# MSS_CTRL_MSS_CTRL register map
Vendor: Texas Instruments
Registers are 32-bit, read-only, reset 0x0 unless marked. A register's access mark holds for its fields unless they carry their own. Offsets are as the file gives them; [hi:lo] are bit positions; {n}, {i} and the like mark numbered series; 'fields as' and 'values as' point back to an identical list.

## MSS_CTRL_MSS_CTRL (part 3 of 5)
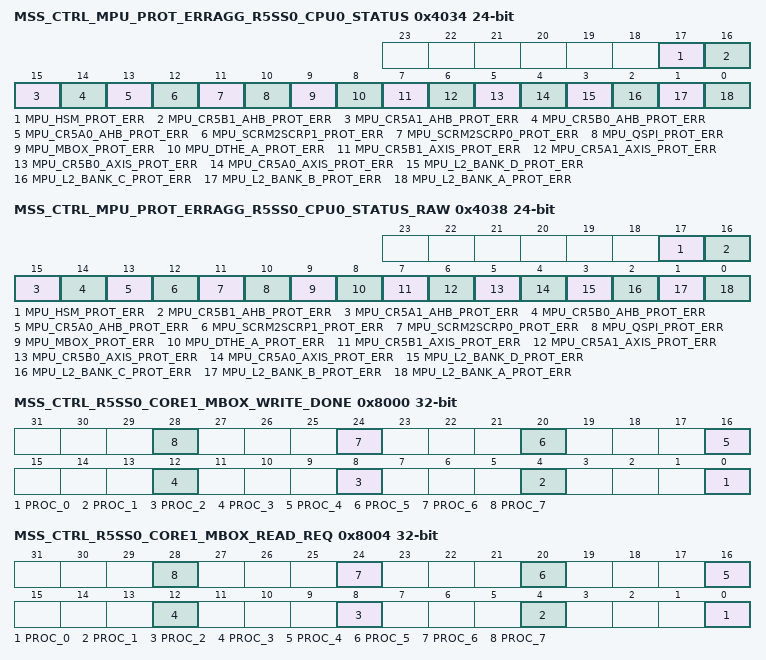
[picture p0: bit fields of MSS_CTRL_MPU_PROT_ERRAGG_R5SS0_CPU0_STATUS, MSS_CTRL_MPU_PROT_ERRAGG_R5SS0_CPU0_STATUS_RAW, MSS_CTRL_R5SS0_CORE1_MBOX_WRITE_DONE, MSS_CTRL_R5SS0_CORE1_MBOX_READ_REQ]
0x4034 MSS_CTRL_MPU_PROT_ERRAGG_R5SS0_CPU0_STATUS 24-bit rw
  [17] MPU_HSM_PROT_ERR — Status of Error from MPU_PROT_INTR. Set only if Interupt is unmasked in MPU_PROT_INTR_ERRAGG_MASKWrie 0x1 to clear this Error.
  [16] MPU_CR5B1_AHB_PROT_ERR — Status of Error from MPU_PROT_INTR. Set only if Interupt is unmasked in MPU_PROT_INTR_ERRAGG_MASKWrie 0x1 to clear this Error.
  [15] MPU_CR5A1_AHB_PROT_ERR — Status of Error from MPU_PROT_INTR. Set only if Interupt is unmasked in MPU_PROT_INTR_ERRAGG_MASKWrie 0x1 to clear this Error.
  [14] MPU_CR5B0_AHB_PROT_ERR — Status of Error from MPU_PROT_INTR. Set only if Interupt is unmasked in MPU_PROT_INTR_ERRAGG_MASKWrie 0x1 to clear this Error.
  [13] MPU_CR5A0_AHB_PROT_ERR — Status of Error from MPU_PROT_INTR. Set only if Interupt is unmasked in MPU_PROT_INTR_ERRAGG_MASKWrie 0x1 to clear this Error.
  [12] MPU_SCRM2SCRP1_PROT_ERR — Status of Error from MPU_PROT_INTR. Set only if Interupt is unmasked in MPU_PROT_INTR_ERRAGG_MASKWrie 0x1 to clear this Error.
  [11] MPU_SCRM2SCRP0_PROT_ERR — Status of Error from MPU_PROT_INTR. Set only if Interupt is unmasked in MPU_PROT_INTR_ERRAGG_MASKWrie 0x1 to clear this Error.
  [10] MPU_QSPI_PROT_ERR — Status of Error from MPU_PROT_INTR. Set only if Interupt is unmasked in MPU_PROT_INTR_ERRAGG_MASKWrie 0x1 to clear this Error.
  [9] MPU_MBOX_PROT_ERR — Status of Error from MPU_PROT_INTR. Set only if Interupt is unmasked in MPU_PROT_INTR_ERRAGG_MASKWrie 0x1 to clear this Error.
  [8] MPU_DTHE_A_PROT_ERR — Status of Error from MPU_PROT_INTR. Set only if Interupt is unmasked in MPU_PROT_INTR_ERRAGG_MASKWrie 0x1 to clear this Error.
  [7] MPU_CR5B1_AXIS_PROT_ERR — Status of Error from MPU_PROT_INTR. Set only if Interupt is unmasked in MPU_PROT_INTR_ERRAGG_MASKWrie 0x1 to clear this Error.
  [6] MPU_CR5A1_AXIS_PROT_ERR — Status of Error from MPU_PROT_INTR. Set only if Interupt is unmasked in MPU_PROT_INTR_ERRAGG_MASKWrie 0x1 to clear this Error.
  [5] MPU_CR5B0_AXIS_PROT_ERR — Status of Error from MPU_PROT_INTR. Set only if Interupt is unmasked in MPU_PROT_INTR_ERRAGG_MASKWrie 0x1 to clear this Error.
  [4] MPU_CR5A0_AXIS_PROT_ERR — Status of Error from MPU_PROT_INTR. Set only if Interupt is unmasked in MPU_PROT_INTR_ERRAGG_MASKWrie 0x1 to clear this Error.
  [3] MPU_L2_BANK_D_PROT_ERR — Status of Error from MPU_PROT_INTR. Set only if Interupt is unmasked in MPU_PROT_INTR_ERRAGG_MASKWrie 0x1 to clear this Error.
  [2] MPU_L2_BANK_C_PROT_ERR — Status of Error from MPU_PROT_INTR. Set only if Interupt is unmasked in MPU_PROT_INTR_ERRAGG_MASKWrie 0x1 to clear this Error.
  [1] MPU_L2_BANK_B_PROT_ERR — Status of Error from MPU_PROT_INTR. Set only if Interupt is unmasked in MPU_PROT_INTR_ERRAGG_MASKWrie 0x1 to clear this Error.
  [0] MPU_L2_BANK_A_PROT_ERR — Status of Error from MPU_PROT_INTR. Set only if Interupt is unmasked in MPU_PROT_INTR_ERRAGG_MASKWrie 0x1 to clear this Error.
0x4038 MSS_CTRL_MPU_PROT_ERRAGG_R5SS0_CPU0_STATUS_RAW 24-bit rw
  [17] MPU_HSM_PROT_ERR — Raw Status of Error from MPU_PROT_INTR. Set irrespective if the Interupt is masked or unmasked in MPU_PROT_INTR_ERRAGG_MASK
  [16] MPU_CR5B1_AHB_PROT_ERR — Raw Status of Error from MPU_PROT_INTR. Set irrespective if the Interupt is masked or unmasked in MPU_PROT_INTR_ERRAGG_MASK
  [15] MPU_CR5A1_AHB_PROT_ERR — Raw Status of Error from MPU_PROT_INTR. Set irrespective if the Interupt is masked or unmasked in MPU_PROT_INTR_ERRAGG_MASK
  [14] MPU_CR5B0_AHB_PROT_ERR — Raw Status of Error from MPU_PROT_INTR. Set irrespective if the Interupt is masked or unmasked in MPU_PROT_INTR_ERRAGG_MASK
  [13] MPU_CR5A0_AHB_PROT_ERR — Raw Status of Error from MPU_PROT_INTR. Set irrespective if the Interupt is masked or unmasked in MPU_PROT_INTR_ERRAGG_MASK
  [12] MPU_SCRM2SCRP1_PROT_ERR — Raw Status of Error from MPU_PROT_INTR. Set irrespective if the Interupt is masked or unmasked in MPU_PROT_INTR_ERRAGG_MASK
  [11] MPU_SCRM2SCRP0_PROT_ERR — Raw Status of Error from MPU_PROT_INTR. Set irrespective if the Interupt is masked or unmasked in MPU_PROT_INTR_ERRAGG_MASK
  [10] MPU_QSPI_PROT_ERR — Raw Status of Error from MPU_PROT_INTR. Set irrespective if the Interupt is masked or unmasked in MPU_PROT_INTR_ERRAGG_MASK
  [9] MPU_MBOX_PROT_ERR — Raw Status of Error from MPU_PROT_INTR. Set irrespective if the Interupt is masked or unmasked in MPU_PROT_INTR_ERRAGG_MASK
  [8] MPU_DTHE_A_PROT_ERR — Raw Status of Error from MPU_PROT_INTR. Set irrespective if the Interupt is masked or unmasked in MPU_PROT_INTR_ERRAGG_MASK
  [7] MPU_CR5B1_AXIS_PROT_ERR — Raw Status of Error from MPU_PROT_INTR. Set irrespective if the Interupt is masked or unmasked in MPU_PROT_INTR_ERRAGG_MASK
  [6] MPU_CR5A1_AXIS_PROT_ERR — Raw Status of Error from MPU_PROT_INTR. Set irrespective if the Interupt is masked or unmasked in MPU_PROT_INTR_ERRAGG_MASK
  [5] MPU_CR5B0_AXIS_PROT_ERR — Raw Status of Error from MPU_PROT_INTR. Set irrespective if the Interupt is masked or unmasked in MPU_PROT_INTR_ERRAGG_MASK
  [4] MPU_CR5A0_AXIS_PROT_ERR — Raw Status of Error from MPU_PROT_INTR. Set irrespective if the Interupt is masked or unmasked in MPU_PROT_INTR_ERRAGG_MASK
  [3] MPU_L2_BANK_D_PROT_ERR — Raw Status of Error from MPU_PROT_INTR. Set irrespective if the Interupt is masked or unmasked in MPU_PROT_INTR_ERRAGG_MASK
  [2] MPU_L2_BANK_C_PROT_ERR — Raw Status of Error from MPU_PROT_INTR. Set irrespective if the Interupt is masked or unmasked in MPU_PROT_INTR_ERRAGG_MASK
  [1] MPU_L2_BANK_B_PROT_ERR — Raw Status of Error from MPU_PROT_INTR. Set irrespective if the Interupt is masked or unmasked in MPU_PROT_INTR_ERRAGG_MASK
  [0] MPU_L2_BANK_A_PROT_ERR — Raw Status of Error from MPU_PROT_INTR. Set irrespective if the Interupt is masked or unmasked in MPU_PROT_INTR_ERRAGG_MASK
0x8000 MSS_CTRL_R5SS0_CORE1_MBOX_WRITE_DONE rw
  [4n] PROC_{n} (n=0..7) — Write pulse bit field:This register should be written once finishing writing into the mailbox memory of processor {n}
0x8004 MSS_CTRL_R5SS0_CORE1_MBOX_READ_REQ rw
  [4n] PROC_{n} (n=0..7) — This is request from processor {n} to mss_CR5B. Requesting it to read from mailbox.
0x8008 MSS_CTRL_R5SS0_CORE1_MBOX_READ_DONE_ACK 8-bit rw
  [7:0] PROC — Write pulse bit field:For bits 0 to 7:Wrting1'b1 : Generates pulse interrupt to corresponding proc from MSS_CR5
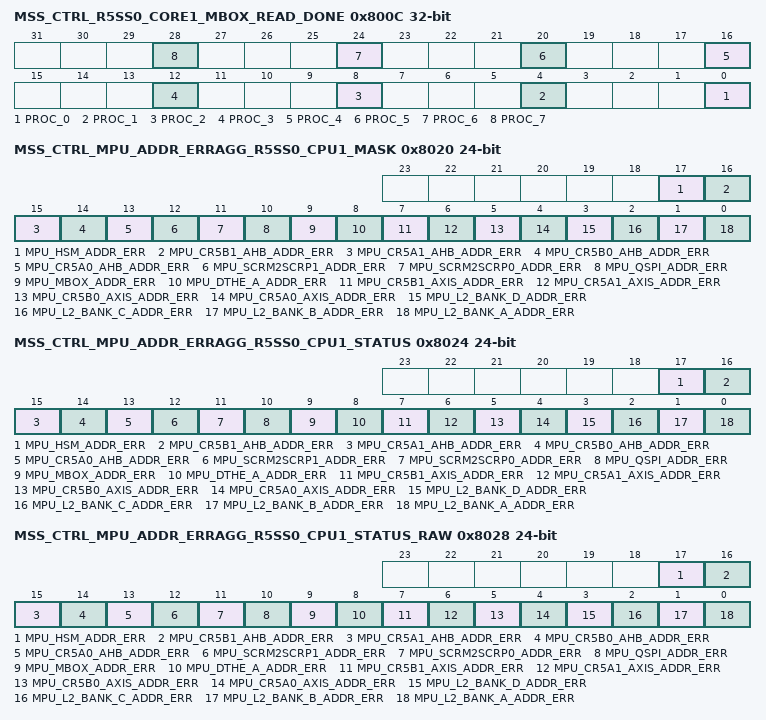
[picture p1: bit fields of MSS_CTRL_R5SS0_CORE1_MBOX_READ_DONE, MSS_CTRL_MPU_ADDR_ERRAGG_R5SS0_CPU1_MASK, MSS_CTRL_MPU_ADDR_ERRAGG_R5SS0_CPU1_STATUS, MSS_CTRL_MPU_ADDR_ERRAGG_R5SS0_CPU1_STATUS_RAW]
0x800C MSS_CTRL_R5SS0_CORE1_MBOX_READ_DONE rw
  [4n] PROC_{n} (n=0..7) — This register should be written once finishing reading from CR5B's mailbox written by proc {n}
0x8010 MSS_CTRL_R5SS0_CORE1_SW_INT size not given rw
  [0] PULSE — Write_pulse bit field:writing 1'b1 to each bit will trigger MSS_SW_INT respectively to CR5A/B.
0x8020 MSS_CTRL_MPU_ADDR_ERRAGG_R5SS0_CPU1_MASK 24-bit rw
  [17] MPU_HSM_ADDR_ERR — Mask Error from MPU_ADDR_INTR to aggregated Error MPU_ADDR_INTR_ERRAGG1 : Error is Masked0 : Error is Unmasked
  [16] MPU_CR5B1_AHB_ADDR_ERR — Mask Error from MPU_ADDR_INTR to aggregated Error MPU_ADDR_INTR_ERRAGG1 : Error is Masked0 : Error is Unmasked
  [15] MPU_CR5A1_AHB_ADDR_ERR — Mask Error from MPU_ADDR_INTR to aggregated Error MPU_ADDR_INTR_ERRAGG1 : Error is Masked0 : Error is Unmasked
  [14] MPU_CR5B0_AHB_ADDR_ERR — Mask Error from MPU_ADDR_INTR to aggregated Error MPU_ADDR_INTR_ERRAGG1 : Error is Masked0 : Error is Unmasked
  [13] MPU_CR5A0_AHB_ADDR_ERR — Mask Error from MPU_ADDR_INTR to aggregated Error MPU_ADDR_INTR_ERRAGG1 : Error is Masked0 : Error is Unmasked
  [12] MPU_SCRM2SCRP1_ADDR_ERR — Mask Error from MPU_ADDR_INTR to aggregated Error MPU_ADDR_INTR_ERRAGG1 : Error is Masked0 : Error is Unmasked
  [11] MPU_SCRM2SCRP0_ADDR_ERR — Mask Error from MPU_ADDR_INTR to aggregated Error MPU_ADDR_INTR_ERRAGG1 : Error is Masked0 : Error is Unmasked
  [10] MPU_QSPI_ADDR_ERR — Mask Error from MPU_ADDR_INTR to aggregated Error MPU_ADDR_INTR_ERRAGG1 : Error is Masked0 : Error is Unmasked
  [9] MPU_MBOX_ADDR_ERR — Mask Error from MPU_ADDR_INTR to aggregated Error MPU_ADDR_INTR_ERRAGG1 : Error is Masked0 : Error is Unmasked
  [8] MPU_DTHE_A_ADDR_ERR — Mask Error from MPU_ADDR_INTR to aggregated Error MPU_ADDR_INTR_ERRAGG1 : Error is Masked0 : Error is Unmasked
  [7] MPU_CR5B1_AXIS_ADDR_ERR — Mask Error from MPU_ADDR_INTR to aggregated Error MPU_ADDR_INTR_ERRAGG1 : Error is Masked0 : Error is Unmasked
  [6] MPU_CR5A1_AXIS_ADDR_ERR — Mask Error from MPU_ADDR_INTR to aggregated Error MPU_ADDR_INTR_ERRAGG1 : Error is Masked0 : Error is Unmasked
  [5] MPU_CR5B0_AXIS_ADDR_ERR — Mask Error from MPU_ADDR_INTR to aggregated Error MPU_ADDR_INTR_ERRAGG1 : Error is Masked0 : Error is Unmasked
  [4] MPU_CR5A0_AXIS_ADDR_ERR — Mask Error from MPU_ADDR_INTR to aggregated Error MPU_ADDR_INTR_ERRAGG1 : Error is Masked0 : Error is Unmasked
  [3] MPU_L2_BANK_D_ADDR_ERR — Mask Error from MPU_ADDR_INTR to aggregated Error MPU_ADDR_INTR_ERRAGG1 : Error is Masked0 : Error is Unmasked
  [2] MPU_L2_BANK_C_ADDR_ERR — Mask Error from MPU_ADDR_INTR to aggregated Error MPU_ADDR_INTR_ERRAGG1 : Error is Masked0 : Error is Unmasked
  [1] MPU_L2_BANK_B_ADDR_ERR — Mask Error from MPU_ADDR_INTR to aggregated Error MPU_ADDR_INTR_ERRAGG1 : Error is Masked0 : Error is Unmasked
  [0] MPU_L2_BANK_A_ADDR_ERR — Mask Error from MPU_ADDR_INTR to aggregated Error MPU_ADDR_INTR_ERRAGG1 : Error is Masked0 : Error is Unmasked
0x8024 MSS_CTRL_MPU_ADDR_ERRAGG_R5SS0_CPU1_STATUS 24-bit rw
  [17] MPU_HSM_ADDR_ERR — Status of Error from MPU_ADDR_INTR. Set only if Interupt is unmasked in MPU_ADDR_INTR_ERRAGG_MASKWrie 0x1 to clear this Error.
  [16] MPU_CR5B1_AHB_ADDR_ERR — Status of Error from MPU_ADDR_INTR. Set only if Interupt is unmasked in MPU_ADDR_INTR_ERRAGG_MASKWrie 0x1 to clear this Error.
  [15] MPU_CR5A1_AHB_ADDR_ERR — Status of Error from MPU_ADDR_INTR. Set only if Interupt is unmasked in MPU_ADDR_INTR_ERRAGG_MASKWrie 0x1 to clear this Error.
  [14] MPU_CR5B0_AHB_ADDR_ERR — Status of Error from MPU_ADDR_INTR. Set only if Interupt is unmasked in MPU_ADDR_INTR_ERRAGG_MASKWrie 0x1 to clear this Error.
  [13] MPU_CR5A0_AHB_ADDR_ERR — Status of Error from MPU_ADDR_INTR. Set only if Interupt is unmasked in MPU_ADDR_INTR_ERRAGG_MASKWrie 0x1 to clear this Error.
  [12] MPU_SCRM2SCRP1_ADDR_ERR — Status of Error from MPU_ADDR_INTR. Set only if Interupt is unmasked in MPU_ADDR_INTR_ERRAGG_MASKWrie 0x1 to clear this Error.
  [11] MPU_SCRM2SCRP0_ADDR_ERR — Status of Error from MPU_ADDR_INTR. Set only if Interupt is unmasked in MPU_ADDR_INTR_ERRAGG_MASKWrie 0x1 to clear this Error.
  [10] MPU_QSPI_ADDR_ERR — Status of Error from MPU_ADDR_INTR. Set only if Interupt is unmasked in MPU_ADDR_INTR_ERRAGG_MASKWrie 0x1 to clear this Error.
  [9] MPU_MBOX_ADDR_ERR — Status of Error from MPU_ADDR_INTR. Set only if Interupt is unmasked in MPU_ADDR_INTR_ERRAGG_MASKWrie 0x1 to clear this Error.
  [8] MPU_DTHE_A_ADDR_ERR — Status of Error from MPU_ADDR_INTR. Set only if Interupt is unmasked in MPU_ADDR_INTR_ERRAGG_MASKWrie 0x1 to clear this Error.
  [7] MPU_CR5B1_AXIS_ADDR_ERR — Status of Error from MPU_ADDR_INTR. Set only if Interupt is unmasked in MPU_ADDR_INTR_ERRAGG_MASKWrie 0x1 to clear this Error.
  [6] MPU_CR5A1_AXIS_ADDR_ERR — Status of Error from MPU_ADDR_INTR. Set only if Interupt is unmasked in MPU_ADDR_INTR_ERRAGG_MASKWrie 0x1 to clear this Error.
  [5] MPU_CR5B0_AXIS_ADDR_ERR — Status of Error from MPU_ADDR_INTR. Set only if Interupt is unmasked in MPU_ADDR_INTR_ERRAGG_MASKWrie 0x1 to clear this Error.
  [4] MPU_CR5A0_AXIS_ADDR_ERR — Status of Error from MPU_ADDR_INTR. Set only if Interupt is unmasked in MPU_ADDR_INTR_ERRAGG_MASKWrie 0x1 to clear this Error.
  [3] MPU_L2_BANK_D_ADDR_ERR — Status of Error from MPU_ADDR_INTR. Set only if Interupt is unmasked in MPU_ADDR_INTR_ERRAGG_MASKWrie 0x1 to clear this Error.
  [2] MPU_L2_BANK_C_ADDR_ERR — Status of Error from MPU_ADDR_INTR. Set only if Interupt is unmasked in MPU_ADDR_INTR_ERRAGG_MASKWrie 0x1 to clear this Error.
  [1] MPU_L2_BANK_B_ADDR_ERR — Status of Error from MPU_ADDR_INTR. Set only if Interupt is unmasked in MPU_ADDR_INTR_ERRAGG_MASKWrie 0x1 to clear this Error.
  [0] MPU_L2_BANK_A_ADDR_ERR — Status of Error from MPU_ADDR_INTR. Set only if Interupt is unmasked in MPU_ADDR_INTR_ERRAGG_MASKWrie 0x1 to clear this Error.
0x8028 MSS_CTRL_MPU_ADDR_ERRAGG_R5SS0_CPU1_STATUS_RAW 24-bit rw
  [17] MPU_HSM_ADDR_ERR — Raw Status of Error from MPU_ADDR_INTR. Set irrespective if the Interupt is masked or unmasked in MPU_ADDR_INTR_ERRAGG_MASK
  [16] MPU_CR5B1_AHB_ADDR_ERR — Raw Status of Error from MPU_ADDR_INTR. Set irrespective if the Interupt is masked or unmasked in MPU_ADDR_INTR_ERRAGG_MASK
  [15] MPU_CR5A1_AHB_ADDR_ERR — Raw Status of Error from MPU_ADDR_INTR. Set irrespective if the Interupt is masked or unmasked in MPU_ADDR_INTR_ERRAGG_MASK
  [14] MPU_CR5B0_AHB_ADDR_ERR — Raw Status of Error from MPU_ADDR_INTR. Set irrespective if the Interupt is masked or unmasked in MPU_ADDR_INTR_ERRAGG_MASK
  [13] MPU_CR5A0_AHB_ADDR_ERR — Raw Status of Error from MPU_ADDR_INTR. Set irrespective if the Interupt is masked or unmasked in MPU_ADDR_INTR_ERRAGG_MASK
  [12] MPU_SCRM2SCRP1_ADDR_ERR — Raw Status of Error from MPU_ADDR_INTR. Set irrespective if the Interupt is masked or unmasked in MPU_ADDR_INTR_ERRAGG_MASK
  [11] MPU_SCRM2SCRP0_ADDR_ERR — Raw Status of Error from MPU_ADDR_INTR. Set irrespective if the Interupt is masked or unmasked in MPU_ADDR_INTR_ERRAGG_MASK
  [10] MPU_QSPI_ADDR_ERR — Raw Status of Error from MPU_ADDR_INTR. Set irrespective if the Interupt is masked or unmasked in MPU_ADDR_INTR_ERRAGG_MASK
  [9] MPU_MBOX_ADDR_ERR — Raw Status of Error from MPU_ADDR_INTR. Set irrespective if the Interupt is masked or unmasked in MPU_ADDR_INTR_ERRAGG_MASK
  [8] MPU_DTHE_A_ADDR_ERR — Raw Status of Error from MPU_ADDR_INTR. Set irrespective if the Interupt is masked or unmasked in MPU_ADDR_INTR_ERRAGG_MASK
  [7] MPU_CR5B1_AXIS_ADDR_ERR — Raw Status of Error from MPU_ADDR_INTR. Set irrespective if the Interupt is masked or unmasked in MPU_ADDR_INTR_ERRAGG_MASK
  [6] MPU_CR5A1_AXIS_ADDR_ERR — Raw Status of Error from MPU_ADDR_INTR. Set irrespective if the Interupt is masked or unmasked in MPU_ADDR_INTR_ERRAGG_MASK
  [5] MPU_CR5B0_AXIS_ADDR_ERR — Raw Status of Error from MPU_ADDR_INTR. Set irrespective if the Interupt is masked or unmasked in MPU_ADDR_INTR_ERRAGG_MASK
  [4] MPU_CR5A0_AXIS_ADDR_ERR — Raw Status of Error from MPU_ADDR_INTR. Set irrespective if the Interupt is masked or unmasked in MPU_ADDR_INTR_ERRAGG_MASK
  [3] MPU_L2_BANK_D_ADDR_ERR — Raw Status of Error from MPU_ADDR_INTR. Set irrespective if the Interupt is masked or unmasked in MPU_ADDR_INTR_ERRAGG_MASK
  [2] MPU_L2_BANK_C_ADDR_ERR — Raw Status of Error from MPU_ADDR_INTR. Set irrespective if the Interupt is masked or unmasked in MPU_ADDR_INTR_ERRAGG_MASK
  [1] MPU_L2_BANK_B_ADDR_ERR — Raw Status of Error from MPU_ADDR_INTR. Set irrespective if the Interupt is masked or unmasked in MPU_ADDR_INTR_ERRAGG_MASK
  [0] MPU_L2_BANK_A_ADDR_ERR — Raw Status of Error from MPU_ADDR_INTR. Set irrespective if the Interupt is masked or unmasked in MPU_ADDR_INTR_ERRAGG_MASK
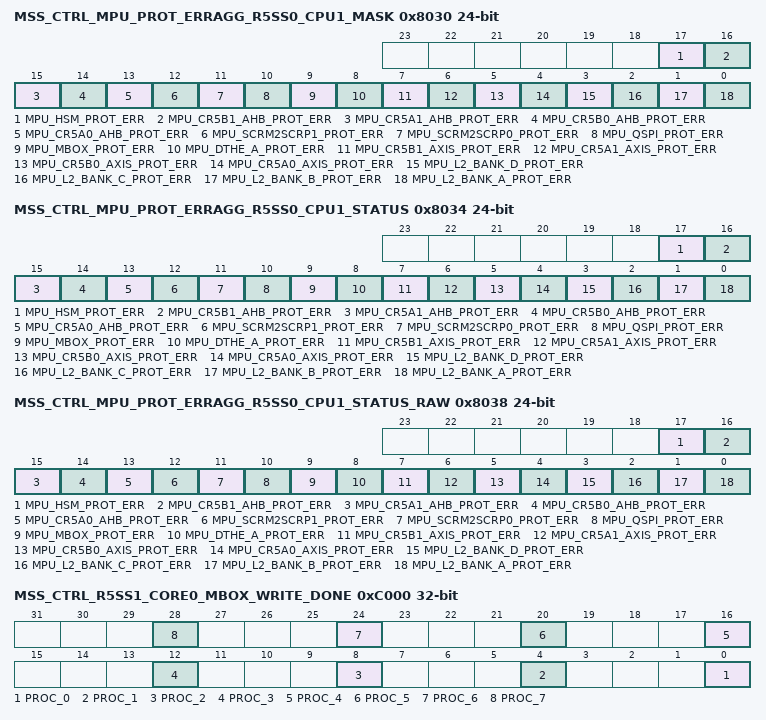
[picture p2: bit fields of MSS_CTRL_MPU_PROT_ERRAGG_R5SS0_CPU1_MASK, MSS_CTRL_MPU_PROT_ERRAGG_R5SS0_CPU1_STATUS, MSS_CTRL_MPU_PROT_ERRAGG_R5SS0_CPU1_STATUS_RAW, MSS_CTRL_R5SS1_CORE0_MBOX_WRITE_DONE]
0x8030 MSS_CTRL_MPU_PROT_ERRAGG_R5SS0_CPU1_MASK 24-bit rw
  [17] MPU_HSM_PROT_ERR — Mask Error from MPU_PROT_INTR to aggregated Error MPU_PROT_INTR_ERRAGG1 : Error is Masked0 : Error is Unmasked
  [16] MPU_CR5B1_AHB_PROT_ERR — Mask Error from MPU_PROT_INTR to aggregated Error MPU_PROT_INTR_ERRAGG1 : Error is Masked0 : Error is Unmasked
  [15] MPU_CR5A1_AHB_PROT_ERR — Mask Error from MPU_PROT_INTR to aggregated Error MPU_PROT_INTR_ERRAGG1 : Error is Masked0 : Error is Unmasked
  [14] MPU_CR5B0_AHB_PROT_ERR — Mask Error from MPU_PROT_INTR to aggregated Error MPU_PROT_INTR_ERRAGG1 : Error is Masked0 : Error is Unmasked
  [13] MPU_CR5A0_AHB_PROT_ERR — Mask Error from MPU_PROT_INTR to aggregated Error MPU_PROT_INTR_ERRAGG1 : Error is Masked0 : Error is Unmasked
  [12] MPU_SCRM2SCRP1_PROT_ERR — Mask Error from MPU_PROT_INTR to aggregated Error MPU_PROT_INTR_ERRAGG1 : Error is Masked0 : Error is Unmasked
  [11] MPU_SCRM2SCRP0_PROT_ERR — Mask Error from MPU_PROT_INTR to aggregated Error MPU_PROT_INTR_ERRAGG1 : Error is Masked0 : Error is Unmasked
  [10] MPU_QSPI_PROT_ERR — Mask Error from MPU_PROT_INTR to aggregated Error MPU_PROT_INTR_ERRAGG1 : Error is Masked0 : Error is Unmasked
  [9] MPU_MBOX_PROT_ERR — Mask Error from MPU_PROT_INTR to aggregated Error MPU_PROT_INTR_ERRAGG1 : Error is Masked0 : Error is Unmasked
  [8] MPU_DTHE_A_PROT_ERR — Mask Error from MPU_PROT_INTR to aggregated Error MPU_PROT_INTR_ERRAGG1 : Error is Masked0 : Error is Unmasked
  [7] MPU_CR5B1_AXIS_PROT_ERR — Mask Error from MPU_PROT_INTR to aggregated Error MPU_PROT_INTR_ERRAGG1 : Error is Masked0 : Error is Unmasked
  [6] MPU_CR5A1_AXIS_PROT_ERR — Mask Error from MPU_PROT_INTR to aggregated Error MPU_PROT_INTR_ERRAGG1 : Error is Masked0 : Error is Unmasked
  [5] MPU_CR5B0_AXIS_PROT_ERR — Mask Error from MPU_PROT_INTR to aggregated Error MPU_PROT_INTR_ERRAGG1 : Error is Masked0 : Error is Unmasked
  [4] MPU_CR5A0_AXIS_PROT_ERR — Mask Error from MPU_PROT_INTR to aggregated Error MPU_PROT_INTR_ERRAGG1 : Error is Masked0 : Error is Unmasked
  [3] MPU_L2_BANK_D_PROT_ERR — Mask Error from MPU_PROT_INTR to aggregated Error MPU_PROT_INTR_ERRAGG1 : Error is Masked0 : Error is Unmasked
  [2] MPU_L2_BANK_C_PROT_ERR — Mask Error from MPU_PROT_INTR to aggregated Error MPU_PROT_INTR_ERRAGG1 : Error is Masked0 : Error is Unmasked
  [1] MPU_L2_BANK_B_PROT_ERR — Mask Error from MPU_PROT_INTR to aggregated Error MPU_PROT_INTR_ERRAGG1 : Error is Masked0 : Error is Unmasked
  [0] MPU_L2_BANK_A_PROT_ERR — Mask Error from MPU_PROT_INTR to aggregated Error MPU_PROT_INTR_ERRAGG1 : Error is Masked0 : Error is Unmasked
0x8034 MSS_CTRL_MPU_PROT_ERRAGG_R5SS0_CPU1_STATUS 24-bit rw
  fields as MSS_CTRL_MPU_PROT_ERRAGG_R5SS0_CPU0_STATUS
0x8038 MSS_CTRL_MPU_PROT_ERRAGG_R5SS0_CPU1_STATUS_RAW 24-bit rw
  fields as MSS_CTRL_MPU_PROT_ERRAGG_R5SS0_CPU0_STATUS_RAW
0xC000 MSS_CTRL_R5SS1_CORE0_MBOX_WRITE_DONE rw
  fields as MSS_CTRL_R5SS0_CORE1_MBOX_WRITE_DONE
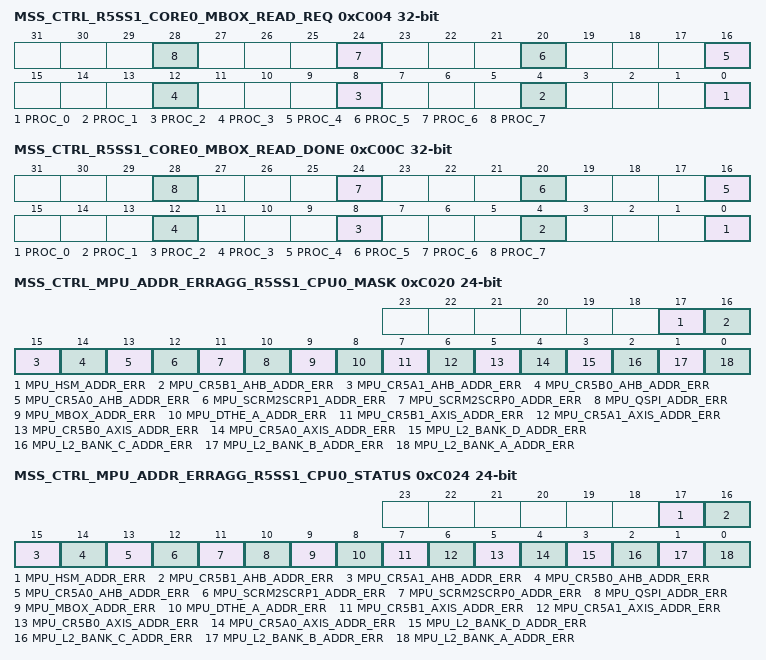
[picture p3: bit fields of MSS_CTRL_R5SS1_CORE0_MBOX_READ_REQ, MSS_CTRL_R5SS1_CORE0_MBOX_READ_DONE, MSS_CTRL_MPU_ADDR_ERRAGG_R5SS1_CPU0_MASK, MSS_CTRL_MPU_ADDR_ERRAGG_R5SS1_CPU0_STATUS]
0xC004 MSS_CTRL_R5SS1_CORE0_MBOX_READ_REQ rw
  [4n] PROC_{n} (n=0..7) — This is request from processor {n} to mss_cr5a. Requesting it to read from mailbox.
0xC008 MSS_CTRL_R5SS1_CORE0_MBOX_READ_DONE_ACK 8-bit rw
  fields as MSS_CTRL_R5SS0_CORE1_MBOX_READ_DONE_ACK
0xC00C MSS_CTRL_R5SS1_CORE0_MBOX_READ_DONE rw
  [4n] PROC_{n} (n=0..7) — This register should be written once finishing reading from CR5A's mailbox written by proc {n}
0xC010 MSS_CTRL_R5SS1_CORE0_SW_INT size not given rw
  fields as MSS_CTRL_R5SS0_CORE1_SW_INT
0xC020 MSS_CTRL_MPU_ADDR_ERRAGG_R5SS1_CPU0_MASK 24-bit rw
  fields as MSS_CTRL_MPU_ADDR_ERRAGG_R5SS0_CPU1_MASK
0xC024 MSS_CTRL_MPU_ADDR_ERRAGG_R5SS1_CPU0_STATUS 24-bit rw
  fields as MSS_CTRL_MPU_ADDR_ERRAGG_R5SS0_CPU1_STATUS
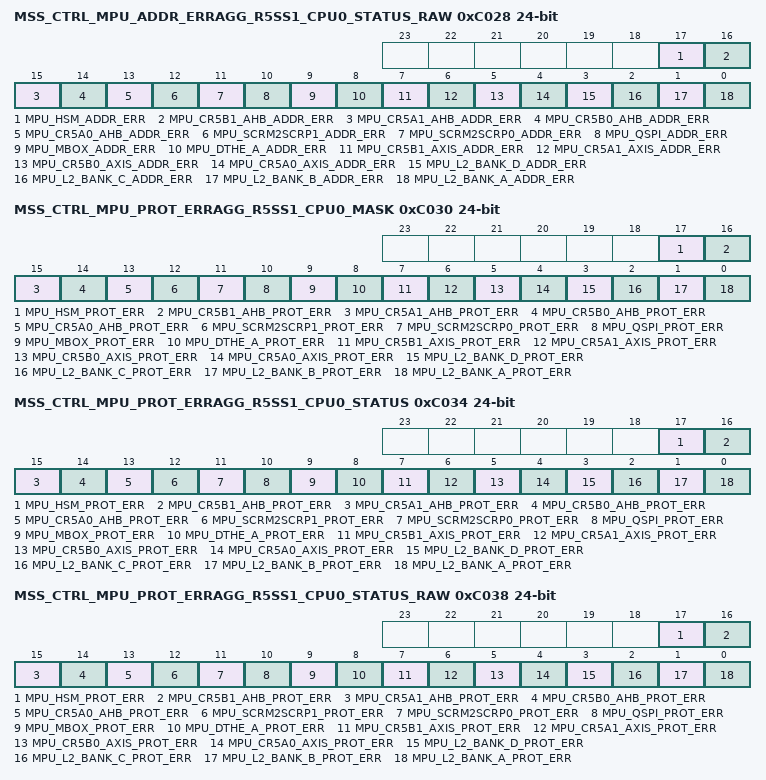
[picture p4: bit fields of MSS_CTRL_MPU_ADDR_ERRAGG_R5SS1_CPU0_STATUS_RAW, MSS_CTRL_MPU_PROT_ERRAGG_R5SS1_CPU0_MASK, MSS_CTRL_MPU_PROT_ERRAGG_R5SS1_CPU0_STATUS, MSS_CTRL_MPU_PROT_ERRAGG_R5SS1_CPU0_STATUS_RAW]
0xC028 MSS_CTRL_MPU_ADDR_ERRAGG_R5SS1_CPU0_STATUS_RAW 24-bit rw
  fields as MSS_CTRL_MPU_ADDR_ERRAGG_R5SS0_CPU1_STATUS_RAW
0xC030 MSS_CTRL_MPU_PROT_ERRAGG_R5SS1_CPU0_MASK 24-bit rw
  fields as MSS_CTRL_MPU_PROT_ERRAGG_R5SS0_CPU1_MASK
0xC034 MSS_CTRL_MPU_PROT_ERRAGG_R5SS1_CPU0_STATUS 24-bit rw
  fields as MSS_CTRL_MPU_PROT_ERRAGG_R5SS0_CPU0_STATUS
0xC038 MSS_CTRL_MPU_PROT_ERRAGG_R5SS1_CPU0_STATUS_RAW 24-bit rw
  fields as MSS_CTRL_MPU_PROT_ERRAGG_R5SS0_CPU0_STATUS_RAW
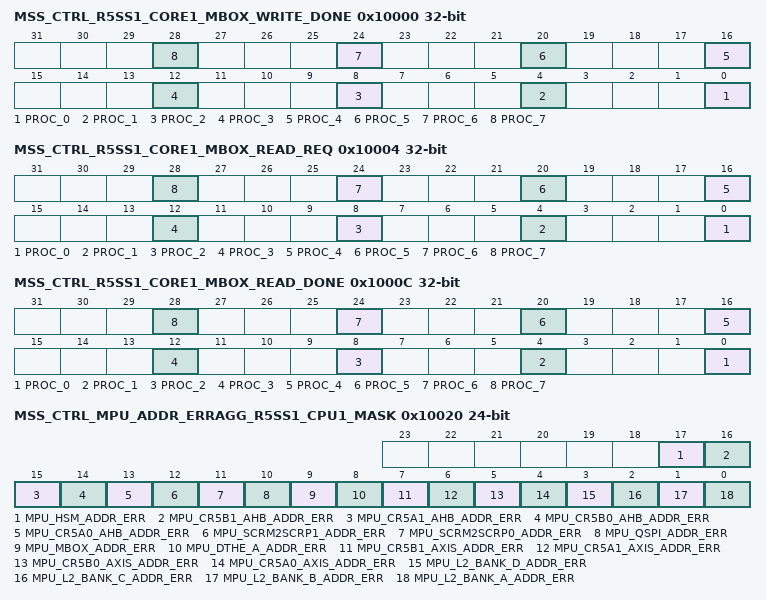
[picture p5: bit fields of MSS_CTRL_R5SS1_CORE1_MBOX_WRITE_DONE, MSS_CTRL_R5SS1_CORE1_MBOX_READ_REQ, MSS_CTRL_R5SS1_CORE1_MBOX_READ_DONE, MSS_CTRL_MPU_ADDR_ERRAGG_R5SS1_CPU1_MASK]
0x10000 MSS_CTRL_R5SS1_CORE1_MBOX_WRITE_DONE rw
  fields as MSS_CTRL_R5SS0_CORE1_MBOX_WRITE_DONE
0x10004 MSS_CTRL_R5SS1_CORE1_MBOX_READ_REQ rw
  fields as MSS_CTRL_R5SS0_CORE1_MBOX_READ_REQ
0x10008 MSS_CTRL_R5SS1_CORE1_MBOX_READ_DONE_ACK 8-bit rw
  fields as MSS_CTRL_R5SS0_CORE1_MBOX_READ_DONE_ACK
0x1000C MSS_CTRL_R5SS1_CORE1_MBOX_READ_DONE rw
  fields as MSS_CTRL_R5SS0_CORE1_MBOX_READ_DONE
0x10010 MSS_CTRL_R5SS1_CORE1_SW_INT size not given rw
  fields as MSS_CTRL_R5SS0_CORE1_SW_INT
0x10020 MSS_CTRL_MPU_ADDR_ERRAGG_R5SS1_CPU1_MASK 24-bit rw
  fields as MSS_CTRL_MPU_ADDR_ERRAGG_R5SS0_CPU1_MASK
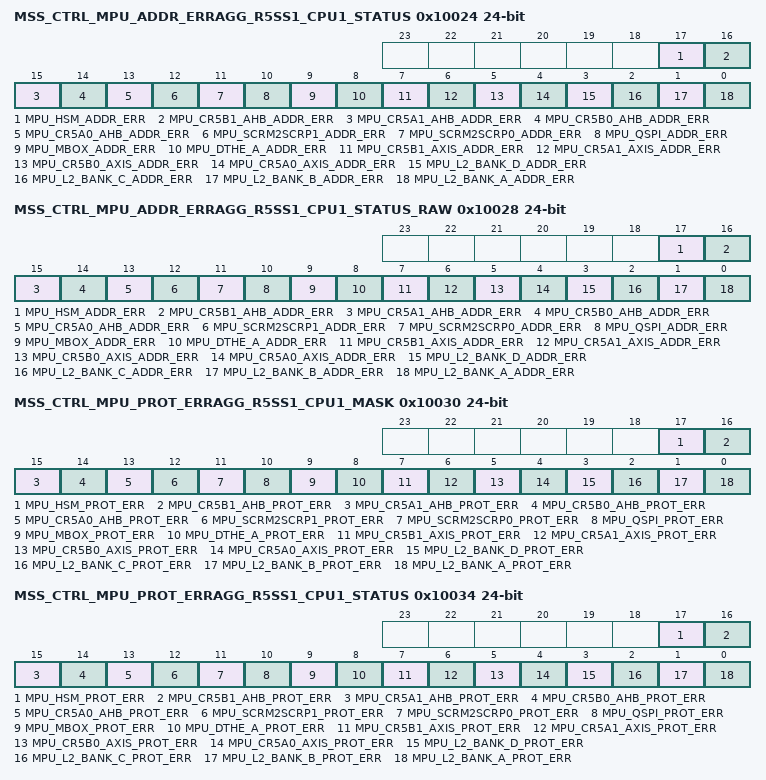
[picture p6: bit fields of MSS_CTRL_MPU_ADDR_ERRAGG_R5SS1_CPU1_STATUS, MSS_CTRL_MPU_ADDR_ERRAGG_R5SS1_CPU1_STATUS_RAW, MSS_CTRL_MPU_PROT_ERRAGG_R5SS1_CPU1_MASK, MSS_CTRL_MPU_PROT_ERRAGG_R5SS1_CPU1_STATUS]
0x10024 MSS_CTRL_MPU_ADDR_ERRAGG_R5SS1_CPU1_STATUS 24-bit rw
  fields as MSS_CTRL_MPU_ADDR_ERRAGG_R5SS0_CPU1_STATUS
0x10028 MSS_CTRL_MPU_ADDR_ERRAGG_R5SS1_CPU1_STATUS_RAW 24-bit rw
  fields as MSS_CTRL_MPU_ADDR_ERRAGG_R5SS0_CPU1_STATUS_RAW
0x10030 MSS_CTRL_MPU_PROT_ERRAGG_R5SS1_CPU1_MASK 24-bit rw
  fields as MSS_CTRL_MPU_PROT_ERRAGG_R5SS0_CPU1_MASK
0x10034 MSS_CTRL_MPU_PROT_ERRAGG_R5SS1_CPU1_STATUS 24-bit rw
  fields as MSS_CTRL_MPU_PROT_ERRAGG_R5SS0_CPU0_STATUS
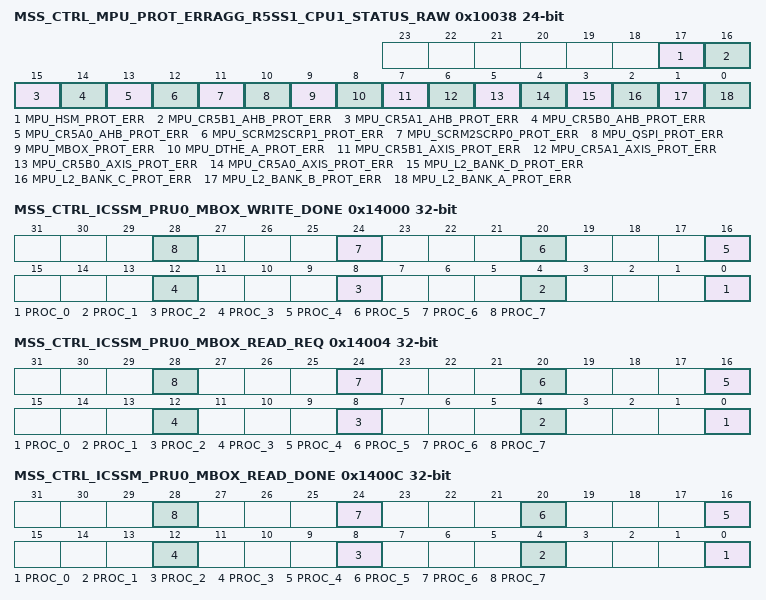
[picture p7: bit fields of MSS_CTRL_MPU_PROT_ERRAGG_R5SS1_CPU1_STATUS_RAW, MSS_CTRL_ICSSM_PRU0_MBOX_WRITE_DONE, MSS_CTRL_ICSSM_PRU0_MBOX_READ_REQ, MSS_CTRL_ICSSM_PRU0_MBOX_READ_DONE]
0x10038 MSS_CTRL_MPU_PROT_ERRAGG_R5SS1_CPU1_STATUS_RAW 24-bit rw
  fields as MSS_CTRL_MPU_PROT_ERRAGG_R5SS0_CPU0_STATUS_RAW
0x14000 MSS_CTRL_ICSSM_PRU0_MBOX_WRITE_DONE rw
  fields as MSS_CTRL_R5SS0_CORE1_MBOX_WRITE_DONE
0x14004 MSS_CTRL_ICSSM_PRU0_MBOX_READ_REQ rw
  [4n] PROC_{n} (n=0..7) — This is request from processor {n} to corresponding ICSSM_PRU. Requesting it to read from mailbox.
0x14008 MSS_CTRL_ICSSM_PRU0_MBOX_READ_DONE_ACK 8-bit rw
  [7:0] PROC — Write pulse bit field:For bits 0 to 7:Wrting1'b1 : Generates pulse interrupt to corresponding proc from ICSSM_PRU0.For bits 8 to 15:Wrting1'b1 : Generates pulse interrupt to corresponding proc from ICSSM_PRU1.
0x1400C MSS_CTRL_ICSSM_PRU0_MBOX_READ_DONE rw
  [4n] PROC_{n} (n=0..7) — This register should be written once finishing reading from corresponding ICSSM_PRU's mailbox written by proc {n}
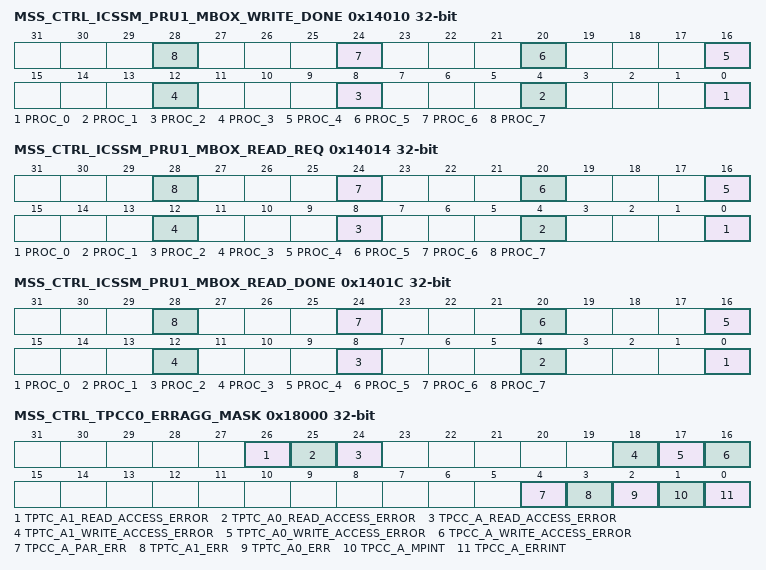
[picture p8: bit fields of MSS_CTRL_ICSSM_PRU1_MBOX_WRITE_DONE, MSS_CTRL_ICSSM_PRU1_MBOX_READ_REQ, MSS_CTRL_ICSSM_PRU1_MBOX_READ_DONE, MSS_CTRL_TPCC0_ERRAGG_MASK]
0x14010 MSS_CTRL_ICSSM_PRU1_MBOX_WRITE_DONE rw
  fields as MSS_CTRL_R5SS0_CORE1_MBOX_WRITE_DONE
0x14014 MSS_CTRL_ICSSM_PRU1_MBOX_READ_REQ rw
  fields as MSS_CTRL_ICSSM_PRU0_MBOX_READ_REQ
0x14018 MSS_CTRL_ICSSM_PRU1_MBOX_READ_DONE_ACK 8-bit rw
  fields as MSS_CTRL_ICSSM_PRU0_MBOX_READ_DONE_ACK
0x1401C MSS_CTRL_ICSSM_PRU1_MBOX_READ_DONE rw
  fields as MSS_CTRL_ICSSM_PRU0_MBOX_READ_DONE
0x18000 MSS_CTRL_TPCC0_ERRAGG_MASK rw
  [26] TPTC_A1_READ_ACCESS_ERROR — Mask Error from MSS_TPTC_A1 to aggregated Error MSS_TPCC_A_ERRAGG1 : Error is Masked0 : Error is Unmasked
  [25] TPTC_A0_READ_ACCESS_ERROR — Mask Error from MSS_TPTC_A0 to aggregated Error MSS_TPCC_A_ERRAGG1 : Error is Masked0 : Error is Unmasked
  [24] TPCC_A_READ_ACCESS_ERROR — Mask Error from MSS_TPCC_A to aggregated Error MSS_TPCC_A_ERRAGG1 : Error is Masked0 : Error is Unmasked
  [18] TPTC_A1_WRITE_ACCESS_ERROR — Mask Error from MSS_TPTC_A1 to aggregated Error MSS_TPCC_A_ERRAGG1 : Error is Masked0 : Error is Unmasked
  [17] TPTC_A0_WRITE_ACCESS_ERROR — Mask Error from MSS_TPTC_A0 to aggregated Error MSS_TPCC_A_ERRAGG1 : Error is Masked0 : Error is Unmasked
  [16] TPCC_A_WRITE_ACCESS_ERROR — Mask Error from MSS_TPCC_A to aggregated Error MSS_TPCC_A_ERRAGG1 : Error is Masked0 : Error is Unmasked
  [4] TPCC_A_PAR_ERR — Mask Error from MSS_TPCC_A to aggregated Error MSS_TPCC_A_ERRAGG1 : Error is Masked0 : Error is Unmasked
  [3] TPTC_A1_ERR — Mask Error from MSS_TPTC_A1 to aggregated Error MSS_TPCC_A_ERRAGG1 : Error is Masked0 : Error is Unmasked
  [2] TPTC_A0_ERR — Mask Error from MSS_TPTC_A0 to aggregated Error MSS_TPCC_A_ERRAGG1 : Error is Masked0 : Error is Unmasked
  [1] TPCC_A_MPINT — Mask Error from MSS_TPCC_A to aggregated Error MSS_TPCC_A_ERRAGG1 : Error is Masked0 : Error is Unmasked
  [0] TPCC_A_ERRINT — Mask Error from MSS_TPCC_A to aggregated Error MSS_TPCC_A_ERRAGG1 : Error is Masked0 : Error is Unmasked
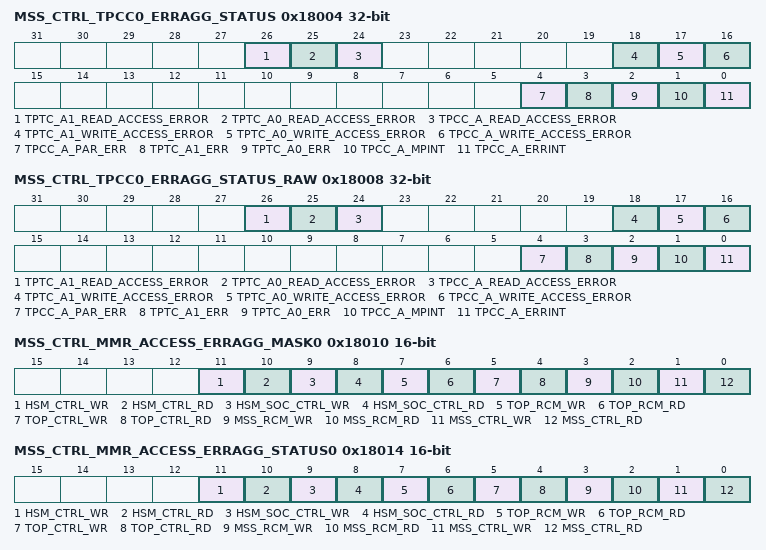
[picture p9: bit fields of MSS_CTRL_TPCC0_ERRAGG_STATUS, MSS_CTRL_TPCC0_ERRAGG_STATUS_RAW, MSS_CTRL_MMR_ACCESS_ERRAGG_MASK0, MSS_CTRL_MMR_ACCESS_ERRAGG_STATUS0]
0x18004 MSS_CTRL_TPCC0_ERRAGG_STATUS rw
  [26] TPTC_A1_READ_ACCESS_ERROR — Status of Error from MSS_TPTC_A1. Set only if Interupt is unmasked in MSS_TPCC_A_ERRAGG_MASKWrie 0x1 to clear this Error.
  [25] TPTC_A0_READ_ACCESS_ERROR — Status of Error from MSS_TPTC_A0. Set only if Interupt is unmasked in MSS_TPCC_A_ERRAGG_MASKWrie 0x1 to clear this Error.
  [24] TPCC_A_READ_ACCESS_ERROR — Status of Error from MSS_TPCC_A. Set only if Interupt is unmasked in MSS_TPCC_A_ERRAGG_MASKWrie 0x1 to clear this Error.
  [18] TPTC_A1_WRITE_ACCESS_ERROR — Status of Error from MSS_TPTC_A1. Set only if Interupt is unmasked in MSS_TPCC_A_ERRAGG_MASKWrie 0x1 to clear this Error.
  [17] TPTC_A0_WRITE_ACCESS_ERROR — Status of Error from MSS_TPTC_A0. Set only if Interupt is unmasked in MSS_TPCC_A_ERRAGG_MASKWrie 0x1 to clear this Error.
  [16] TPCC_A_WRITE_ACCESS_ERROR — Status of Error from MSS_TPCC_A. Set only if Interupt is unmasked in MSS_TPCC_A_ERRAGG_MASKWrie 0x1 to clear this Error.
  [4] TPCC_A_PAR_ERR — Status of Error from MSS_TPCC_A. Set only if Interupt is unmasked in MSS_TPCC_A_ERRAGG_MASKWrie 0x1 to clear this Error.
  [3] TPTC_A1_ERR — Status of Error from MSS_TPTC_A1. Set only if Interupt is unmasked in MSS_TPCC_A_ERRAGG_MASKWrie 0x1 to clear this Error.
  [2] TPTC_A0_ERR — Status of Error from MSS_TPTC_A0. Set only if Interupt is unmasked in MSS_TPCC_A_ERRAGG_MASKWrie 0x1 to clear this Error.
  [1] TPCC_A_MPINT — Status of Error from MSS_TPCC_A. Set only if Interupt is unmasked in MSS_TPCC_A_ERRAGG_MASKWrie 0x1 to clear this Error.
  [0] TPCC_A_ERRINT — Status of Error from MSS_TPCC_A. Set only if Interupt is unmasked in MSS_TPCC_A_ERRAGG_MASKWrie 0x1 to clear this Error.
0x18008 MSS_CTRL_TPCC0_ERRAGG_STATUS_RAW rw
  [26] TPTC_A1_READ_ACCESS_ERROR — Raw Status of Error from MSS_TPTC_A1. Set irrespective if the Interupt is masked or unmasked in MSS_TPCC_A_ERRAGG_MASK
  [25] TPTC_A0_READ_ACCESS_ERROR — Raw Status of Error from MSS_TPTC_A0. Set irrespective if the Interupt is masked or unmasked in MSS_TPCC_A_ERRAGG_MASK
  [24] TPCC_A_READ_ACCESS_ERROR — Raw Status of Error from MSS_TPCC_A. Set irrespective if the Interupt is masked or unmasked in MSS_TPCC_A_ERRAGG_MASK
  [18] TPTC_A1_WRITE_ACCESS_ERROR — Raw Status of Error from MSS_TPTC_A1. Set irrespective if the Interupt is masked or unmasked in MSS_TPCC_A_ERRAGG_MASK
  [17] TPTC_A0_WRITE_ACCESS_ERROR — Raw Status of Error from MSS_TPTC_A0. Set irrespective if the Interupt is masked or unmasked in MSS_TPCC_A_ERRAGG_MASK
  [16] TPCC_A_WRITE_ACCESS_ERROR — Raw Status of Error from MSS_TPCC_A. Set irrespective if the Interupt is masked or unmasked in MSS_TPCC_A_ERRAGG_MASK
  [4] TPCC_A_PAR_ERR — Raw Status of Error from MSS_TPCC_A. Set irrespective if the Interupt is masked or unmasked in MSS_TPCC_A_ERRAGG_MASK
  [3] TPTC_A1_ERR — Raw Status of Error from MSS_TPTC_A1. Set irrespective if the Interupt is masked or unmasked in MSS_TPCC_A_ERRAGG_MASK
  [2] TPTC_A0_ERR — Raw Status of Error from MSS_TPTC_A0. Set irrespective if the Interupt is masked or unmasked in MSS_TPCC_A_ERRAGG_MASK
  [1] TPCC_A_MPINT — Raw Status of Error from MSS_TPCC_A. Set irrespective if the Interupt is masked or unmasked in MSS_TPCC_A_ERRAGG_MASK
  [0] TPCC_A_ERRINT — Raw Status of Error from MSS_TPCC_A. Set irrespective if the Interupt is masked or unmasked in MSS_TPCC_A_ERRAGG_MASK
0x18010 MSS_CTRL_MMR_ACCESS_ERRAGG_MASK0 16-bit rw
  [11] HSM_CTRL_WR — Mask Interrupt from HSM_CTRL to aggregated Interrupt MSS_PERIPH_ACCESS_ERRAGG1 : Interrupt is Masked0 : Interrupt is Unmasked
  [10] HSM_CTRL_RD — Mask Interrupt from HSM_CTRL to aggregated Interrupt MSS_PERIPH_ACCESS_ERRAGG1 : Interrupt is Masked0 : Interrupt is Unmasked
  [9] HSM_SOC_CTRL_WR — Mask Interrupt from HSM_SOC_CTRL to aggregated Interrupt MSS_PERIPH_ACCESS_ERRAGG1 : Interrupt is Masked0 : Interrupt is Unmasked
  [8] HSM_SOC_CTRL_RD — Mask Interrupt from HSM_SOC_CTRL to aggregated Interrupt MSS_PERIPH_ACCESS_ERRAGG1 : Interrupt is Masked0 : Interrupt is Unmasked
  [7] TOP_RCM_WR — Mask Interrupt from TOP_RCM to aggregated Interrupt MSS_PERIPH_ACCESS_ERRAGG1 : Interrupt is Masked0 : Interrupt is Unmasked
  [6] TOP_RCM_RD — Mask Interrupt from TOP_RCM to aggregated Interrupt MSS_PERIPH_ACCESS_ERRAGG1 : Interrupt is Masked0 : Interrupt is Unmasked
  [5] TOP_CTRL_WR — Mask Interrupt from TOP_CTRL to aggregated Interrupt MSS_PERIPH_ACCESS_ERRAGG1 : Interrupt is Masked0 : Interrupt is Unmasked
  [4] TOP_CTRL_RD — Mask Interrupt from TOP_CTRL to aggregated Interrupt MSS_PERIPH_ACCESS_ERRAGG1 : Interrupt is Masked0 : Interrupt is Unmasked
  [3] MSS_RCM_WR — Mask Interrupt from MSS_RCM to aggregated Interrupt MSS_PERIPH_ACCESS_ERRAGG1 : Interrupt is Masked0 : Interrupt is Unmasked
  [2] MSS_RCM_RD — Mask Interrupt from MSS_RCM to aggregated Interrupt MSS_PERIPH_ACCESS_ERRAGG1 : Interrupt is Masked0 : Interrupt is Unmasked
  [1] MSS_CTRL_WR — Mask Interrupt from MSS_CTRL to aggregated Interrupt MSS_PERIPH_ACCESS_ERRAGG1 : Interrupt is Masked0 : Interrupt is Unmasked
  [0] MSS_CTRL_RD — Mask Interrupt from MSS_CTRL to aggregated Interrupt MSS_PERIPH_ACCESS_ERRAGG1 : Interrupt is Masked0 : Interrupt is Unmasked
0x18014 MSS_CTRL_MMR_ACCESS_ERRAGG_STATUS0 16-bit rw
  [11] HSM_CTRL_WR — Status of Interrupt from HSM_CTRLSet only if Interupt is unmasked in MSS_PERIPH_ERRAGG_MASK0Wrie 0x1 to clear this interrupt.
  [10] HSM_CTRL_RD — Status of Interrupt from HSM_CTRLSet only if Interupt is unmasked in MSS_PERIPH_ERRAGG_MASK0Wrie 0x1 to clear this interrupt.
  [9] HSM_SOC_CTRL_WR — Status of Interrupt from HSM_SOC_CTRLSet only if Interupt is unmasked in MSS_PERIPH_ERRAGG_MASK0Wrie 0x1 to clear this interrupt.
  [8] HSM_SOC_CTRL_RD — Status of Interrupt from HSM_SOC_CTRLSet only if Interupt is unmasked in MSS_PERIPH_ERRAGG_MASK0Wrie 0x1 to clear this interrupt.
  [7] TOP_RCM_WR — Status of Interrupt from TOP_RCMSet only if Interupt is unmasked in MSS_PERIPH_ERRAGG_MASK0Wrie 0x1 to clear this interrupt.
  [6] TOP_RCM_RD — Status of Interrupt from TOP_RCMSet only if Interupt is unmasked in MSS_PERIPH_ERRAGG_MASK0Wrie 0x1 to clear this interrupt.
  [5] TOP_CTRL_WR — Status of Interrupt from TOP_CTRLSet only if Interupt is unmasked in MSS_PERIPH_ERRAGG_MASK0Wrie 0x1 to clear this interrupt.
  [4] TOP_CTRL_RD — Status of Interrupt from TOP_CTRLSet only if Interupt is unmasked in MSS_PERIPH_ERRAGG_MASK0Wrie 0x1 to clear this interrupt.
  [3] MSS_RCM_WR — Status of Interrupt from MSS_RCMSet only if Interupt is unmasked in MSS_PERIPH_ERRAGG_MASK0Wrie 0x1 to clear this interrupt.
  [2] MSS_RCM_RD — Status of Interrupt from MSS_RCMSet only if Interupt is unmasked in MSS_PERIPH_ERRAGG_MASK0Wrie 0x1 to clear this interrupt.
  [1] MSS_CTRL_WR — Status of Interrupt from MSS_CTRLSet only if Interupt is unmasked in MSS_PERIPH_ERRAGG_MASK0Wrie 0x1 to clear this interrupt.
  [0] MSS_CTRL_RD — Status of Interrupt from MSS_CTRLSet only if Interupt is unmasked in MSS_PERIPH_ERRAGG_MASK0Wrie 0x1 to clear this interrupt.
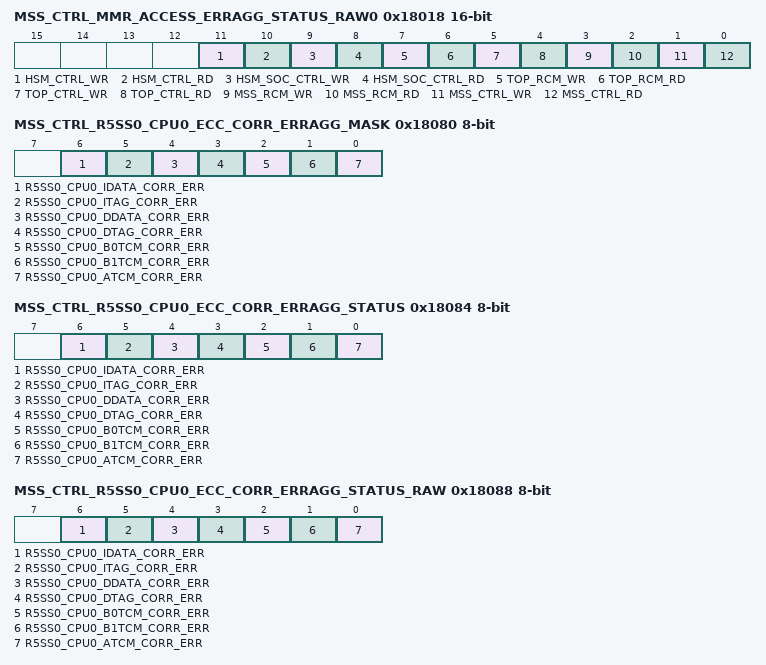
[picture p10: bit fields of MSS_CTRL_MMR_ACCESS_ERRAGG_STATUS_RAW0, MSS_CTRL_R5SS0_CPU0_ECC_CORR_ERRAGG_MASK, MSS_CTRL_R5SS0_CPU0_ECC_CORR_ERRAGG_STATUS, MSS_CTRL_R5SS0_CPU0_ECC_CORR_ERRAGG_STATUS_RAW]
0x18018 MSS_CTRL_MMR_ACCESS_ERRAGG_STATUS_RAW0 16-bit rw
  [11] HSM_CTRL_WR — Raw Status of Interrupt from HSM_CTRL. Set irrespective if the Interupt is masked or unmasked in MSS_PERIPH_ERRAGG_MASK0
  [10] HSM_CTRL_RD — Raw Status of Interrupt from HSM_CTRL. Set irrespective if the Interupt is masked or unmasked in MSS_PERIPH_ERRAGG_MASK0
  [9] HSM_SOC_CTRL_WR — Raw Status of Interrupt from HSM_SOC_CTRL. Set irrespective if the Interupt is masked or unmasked in MSS_PERIPH_ERRAGG_MASK0
  [8] HSM_SOC_CTRL_RD — Raw Status of Interrupt from HSM_SOC_CTRL. Set irrespective if the Interupt is masked or unmasked in MSS_PERIPH_ERRAGG_MASK0
  [7] TOP_RCM_WR — Raw Status of Interrupt from TOP_RCM. Set irrespective if the Interupt is masked or unmasked in MSS_PERIPH_ERRAGG_MASK0
  [6] TOP_RCM_RD — Raw Status of Interrupt from TOP_RCM. Set irrespective if the Interupt is masked or unmasked in MSS_PERIPH_ERRAGG_MASK0
  [5] TOP_CTRL_WR — Raw Status of Interrupt from TOP_CTRL. Set irrespective if the Interupt is masked or unmasked in MSS_PERIPH_ERRAGG_MASK0
  [4] TOP_CTRL_RD — Raw Status of Interrupt from TOP_CTRL. Set irrespective if the Interupt is masked or unmasked in MSS_PERIPH_ERRAGG_MASK0
  [3] MSS_RCM_WR — Raw Status of Interrupt from MSS_RCM. Set irrespective if the Interupt is masked or unmasked in MSS_PERIPH_ERRAGG_MASK0
  [2] MSS_RCM_RD — Raw Status of Interrupt from MSS_RCM. Set irrespective if the Interupt is masked or unmasked in MSS_PERIPH_ERRAGG_MASK0
  [1] MSS_CTRL_WR — Raw Status of Interrupt from MSS_CTRL. Set irrespective if the Interupt is masked or unmasked in MSS_PERIPH_ERRAGG_MASK0
  [0] MSS_CTRL_RD — Raw Status of Interrupt from MSS_CTRL. Set irrespective if the Interupt is masked or unmasked in MSS_PERIPH_ERRAGG_MASK0
0x18080 MSS_CTRL_R5SS0_CPU0_ECC_CORR_ERRAGG_MASK 8-bit rw
  [6] R5SS0_CPU0_IDATA_CORR_ERR — Mask Interrupt for correctable errors to aggregated Interrupt of corresponding CPU1 : Interrupt is Masked0 : Interrupt is Unmasked
  [5] R5SS0_CPU0_ITAG_CORR_ERR — Mask Interrupt for correctable errors to aggregated Interrupt of corresponding CPU1 : Interrupt is Masked0 : Interrupt is Unmasked
  [4] R5SS0_CPU0_DDATA_CORR_ERR — Mask Interrupt for correctable errors to aggregated Interrupt of corresponding CPU1 : Interrupt is Masked0 : Interrupt is Unmasked
  [3] R5SS0_CPU0_DTAG_CORR_ERR — Mask Interrupt for correctable errors to aggregated Interrupt of corresponding CPU1 : Interrupt is Masked0 : Interrupt is Unmasked
  [2] R5SS0_CPU0_B0TCM_CORR_ERR — Mask Interrupt for correctable errors to aggregated Interrupt of corresponding CPU1 : Interrupt is Masked0 : Interrupt is Unmasked
  [1] R5SS0_CPU0_B1TCM_CORR_ERR — Mask Interrupt for correctable errors to aggregated Interrupt of corresponding CPU1 : Interrupt is Masked0 : Interrupt is Unmasked
  [0] R5SS0_CPU0_ATCM_CORR_ERR — Mask Interrupt for correctable errors to aggregated Interrupt of corresponding CPU1 : Interrupt is Masked0 : Interrupt is Unmasked
0x18084 MSS_CTRL_R5SS0_CPU0_ECC_CORR_ERRAGG_STATUS 8-bit rw
  [6] R5SS0_CPU0_IDATA_CORR_ERR — Status of Interrupt from correctable error of corresponding CPUSet only if Interupt is unmasked in corresponding R5SS*_CPU*_ECC_CORR_ERRAGG_MASK registerWrie 0x1 to clear this interrupt.
  [5] R5SS0_CPU0_ITAG_CORR_ERR — Status of Interrupt from correctable error of corresponding CPUSet only if Interupt is unmasked in corresponding R5SS*_CPU*_ECC_CORR_ERRAGG_MASK registerWrie 0x1 to clear this interrupt.
  [4] R5SS0_CPU0_DDATA_CORR_ERR — Status of Interrupt from correctable error of corresponding CPUSet only if Interupt is unmasked in corresponding R5SS*_CPU*_ECC_CORR_ERRAGG_MASK registerWrie 0x1 to clear this interrupt.
  [3] R5SS0_CPU0_DTAG_CORR_ERR — Status of Interrupt from correctable error of corresponding CPUSet only if Interupt is unmasked in corresponding R5SS*_CPU*_ECC_CORR_ERRAGG_MASK registerWrie 0x1 to clear this interrupt.
  [2] R5SS0_CPU0_B0TCM_CORR_ERR — Status of Interrupt from correctable error of corresponding CPUSet only if Interupt is unmasked in corresponding R5SS*_CPU*_ECC_CORR_ERRAGG_MASK registerWrie 0x1 to clear this interrupt.
  [1] R5SS0_CPU0_B1TCM_CORR_ERR — Status of Interrupt from correctable error of corresponding CPUSet only if Interupt is unmasked in corresponding R5SS*_CPU*_ECC_CORR_ERRAGG_MASK registerWrie 0x1 to clear this interrupt.
  [0] R5SS0_CPU0_ATCM_CORR_ERR — Status of Interrupt from correctable error of corresponding CPUSet only if Interupt is unmasked in corresponding R5SS*_CPU*_ECC_CORR_ERRAGG_MASK registerWrie 0x1 to clear this interrupt.
0x18088 MSS_CTRL_R5SS0_CPU0_ECC_CORR_ERRAGG_STATUS_RAW 8-bit rw
  [6] R5SS0_CPU0_IDATA_CORR_ERR — Raw Status of Interrupt from correctable error of corresponding CPUSet only if Interupt is unmasked in corresponding R5SS*_CPU*_ECC_CORR_ERRAGG_MASK registerWrie 0x1 to clear this interrupt.
  [5] R5SS0_CPU0_ITAG_CORR_ERR — Raw Status of Interrupt from correctable error of corresponding CPUSet only if Interupt is unmasked in corresponding R5SS*_CPU*_ECC_CORR_ERRAGG_MASK registerWrie 0x1 to clear this interrupt.
  [4] R5SS0_CPU0_DDATA_CORR_ERR — Raw Status of Interrupt from correctable error of corresponding CPUSet only if Interupt is unmasked in corresponding R5SS*_CPU*_ECC_CORR_ERRAGG_MASK registerWrie 0x1 to clear this interrupt.
  [3] R5SS0_CPU0_DTAG_CORR_ERR — Raw Status of Interrupt from correctable error of corresponding CPUSet only if Interupt is unmasked in corresponding R5SS*_CPU*_ECC_CORR_ERRAGG_MASK registerWrie 0x1 to clear this interrupt.
  [2] R5SS0_CPU0_B0TCM_CORR_ERR — Raw Status of Interrupt from correctable error of corresponding CPUSet only if Interupt is unmasked in corresponding R5SS*_CPU*_ECC_CORR_ERRAGG_MASK registerWrie 0x1 to clear this interrupt.
  [1] R5SS0_CPU0_B1TCM_CORR_ERR — Raw Status of Interrupt from correctable error of corresponding CPUSet only if Interupt is unmasked in corresponding R5SS*_CPU*_ECC_CORR_ERRAGG_MASK registerWrie 0x1 to clear this interrupt.
  [0] R5SS0_CPU0_ATCM_CORR_ERR — Raw Status of Interrupt from correctable error of corresponding CPUSet only if Interupt is unmasked in corresponding R5SS*_CPU*_ECC_CORR_ERRAGG_MASK registerWrie 0x1 to clear this interrupt.
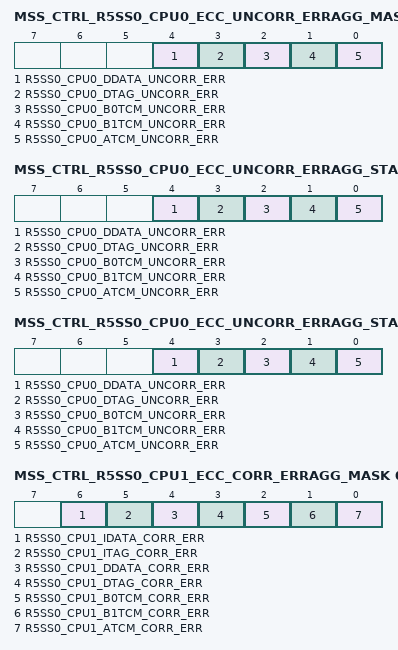
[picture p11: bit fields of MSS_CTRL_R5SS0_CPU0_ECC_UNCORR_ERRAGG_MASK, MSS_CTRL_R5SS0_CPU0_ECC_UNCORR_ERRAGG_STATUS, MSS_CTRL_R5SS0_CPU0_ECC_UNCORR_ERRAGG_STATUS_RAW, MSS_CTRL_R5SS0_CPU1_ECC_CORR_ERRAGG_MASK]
0x18090 MSS_CTRL_R5SS0_CPU0_ECC_UNCORR_ERRAGG_MASK 8-bit rw
  [4] R5SS0_CPU0_DDATA_UNCORR_ERR — Mask Interrupt for correctable errors to aggregated Interrupt of corresponding CPU1 : Interrupt is Masked0 : Interrupt is Unmasked
  [3] R5SS0_CPU0_DTAG_UNCORR_ERR — Mask Interrupt for correctable errors to aggregated Interrupt of corresponding CPU1 : Interrupt is Masked0 : Interrupt is Unmasked
  [2] R5SS0_CPU0_B0TCM_UNCORR_ERR — Mask Interrupt for correctable errors to aggregated Interrupt of corresponding CPU1 : Interrupt is Masked0 : Interrupt is Unmasked
  [1] R5SS0_CPU0_B1TCM_UNCORR_ERR — Mask Interrupt for correctable errors to aggregated Interrupt of corresponding CPU1 : Interrupt is Masked0 : Interrupt is Unmasked
  [0] R5SS0_CPU0_ATCM_UNCORR_ERR — Mask Interrupt for correctable errors to aggregated Interrupt of corresponding CPU1 : Interrupt is Masked0 : Interrupt is Unmasked
0x18094 MSS_CTRL_R5SS0_CPU0_ECC_UNCORR_ERRAGG_STATUS 8-bit rw
  [4] R5SS0_CPU0_DDATA_UNCORR_ERR — Status of Interrupt from correctable error of corresponding CPUSet only if Interupt is unmasked in corresponding R5SS*_CPU*_ECC_UNCORR_ERRAGG_MASK registerWrie 0x1 to clear this interrupt.
  [3] R5SS0_CPU0_DTAG_UNCORR_ERR — Status of Interrupt from correctable error of corresponding CPUSet only if Interupt is unmasked in corresponding R5SS*_CPU*_ECC_UNCORR_ERRAGG_MASK registerWrie 0x1 to clear this interrupt.
  [2] R5SS0_CPU0_B0TCM_UNCORR_ERR — Status of Interrupt from correctable error of corresponding CPUSet only if Interupt is unmasked in corresponding R5SS*_CPU*_ECC_UNCORR_ERRAGG_MASK registerWrie 0x1 to clear this interrupt.
  [1] R5SS0_CPU0_B1TCM_UNCORR_ERR — Status of Interrupt from correctable error of corresponding CPUSet only if Interupt is unmasked in corresponding R5SS*_CPU*_ECC_UNCORR_ERRAGG_MASK registerWrie 0x1 to clear this interrupt.
  [0] R5SS0_CPU0_ATCM_UNCORR_ERR — Status of Interrupt from correctable error of corresponding CPUSet only if Interupt is unmasked in corresponding R5SS*_CPU*_ECC_UNCORR_ERRAGG_MASK registerWrie 0x1 to clear this interrupt.
0x18098 MSS_CTRL_R5SS0_CPU0_ECC_UNCORR_ERRAGG_STATUS_RAW 8-bit rw
  [4] R5SS0_CPU0_DDATA_UNCORR_ERR — Raw Status of Interrupt from correctable error of corresponding CPUSet only if Interupt is unmasked in corresponding R5SS*_CPU*_ECC_UNCORR_ERRAGG_MASK registerWrie 0x1 to clear this interrupt.
  [3] R5SS0_CPU0_DTAG_UNCORR_ERR — Raw Status of Interrupt from correctable error of corresponding CPUSet only if Interupt is unmasked in corresponding R5SS*_CPU*_ECC_UNCORR_ERRAGG_MASK registerWrie 0x1 to clear this interrupt.
  [2] R5SS0_CPU0_B0TCM_UNCORR_ERR — Raw Status of Interrupt from correctable error of corresponding CPUSet only if Interupt is unmasked in corresponding R5SS*_CPU*_ECC_UNCORR_ERRAGG_MASK registerWrie 0x1 to clear this interrupt.
  [1] R5SS0_CPU0_B1TCM_UNCORR_ERR — Raw Status of Interrupt from correctable error of corresponding CPUSet only if Interupt is unmasked in corresponding R5SS*_CPU*_ECC_UNCORR_ERRAGG_MASK registerWrie 0x1 to clear this interrupt.
  [0] R5SS0_CPU0_ATCM_UNCORR_ERR — Raw Status of Interrupt from correctable error of corresponding CPUSet only if Interupt is unmasked in corresponding R5SS*_CPU*_ECC_UNCORR_ERRAGG_MASK registerWrie 0x1 to clear this interrupt.
0x180A0 MSS_CTRL_R5SS0_CPU1_ECC_CORR_ERRAGG_MASK 8-bit rw
  [6] R5SS0_CPU1_IDATA_CORR_ERR — Mask Interrupt for correctable errors to aggregated Interrupt of corresponding CPU1 : Interrupt is Masked0 : Interrupt is Unmasked
  [5] R5SS0_CPU1_ITAG_CORR_ERR — Mask Interrupt for correctable errors to aggregated Interrupt of corresponding CPU1 : Interrupt is Masked0 : Interrupt is Unmasked
  [4] R5SS0_CPU1_DDATA_CORR_ERR — Mask Interrupt for correctable errors to aggregated Interrupt of corresponding CPU1 : Interrupt is Masked0 : Interrupt is Unmasked
  [3] R5SS0_CPU1_DTAG_CORR_ERR — Mask Interrupt for correctable errors to aggregated Interrupt of corresponding CPU1 : Interrupt is Masked0 : Interrupt is Unmasked
  [2] R5SS0_CPU1_B0TCM_CORR_ERR — Mask Interrupt for correctable errors to aggregated Interrupt of corresponding CPU1 : Interrupt is Masked0 : Interrupt is Unmasked
  [1] R5SS0_CPU1_B1TCM_CORR_ERR — Mask Interrupt for correctable errors to aggregated Interrupt of corresponding CPU1 : Interrupt is Masked0 : Interrupt is Unmasked
  [0] R5SS0_CPU1_ATCM_CORR_ERR — Mask Interrupt for correctable errors to aggregated Interrupt of corresponding CPU1 : Interrupt is Masked0 : Interrupt is Unmasked
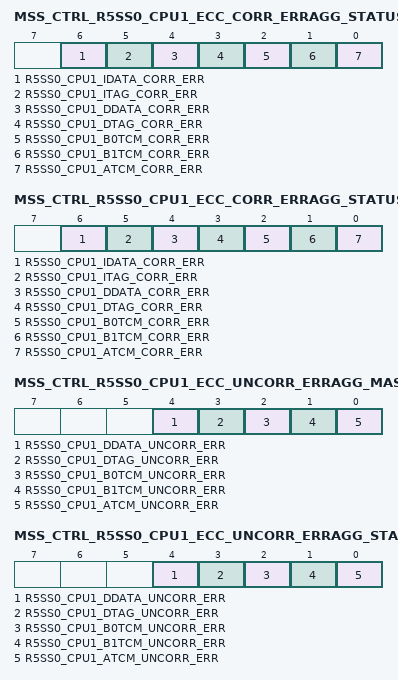
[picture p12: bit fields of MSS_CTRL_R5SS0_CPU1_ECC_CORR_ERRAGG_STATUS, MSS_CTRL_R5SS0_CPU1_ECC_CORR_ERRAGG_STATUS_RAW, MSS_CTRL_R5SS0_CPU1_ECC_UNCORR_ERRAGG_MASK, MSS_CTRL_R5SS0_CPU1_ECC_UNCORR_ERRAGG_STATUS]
0x180A4 MSS_CTRL_R5SS0_CPU1_ECC_CORR_ERRAGG_STATUS 8-bit rw
  [6] R5SS0_CPU1_IDATA_CORR_ERR — Status of Interrupt from correctable error of corresponding CPUSet only if Interupt is unmasked in corresponding R5SS*_CPU*_ECC_CORR_ERRAGG_MASK registerWrie 0x1 to clear this interrupt.
  [5] R5SS0_CPU1_ITAG_CORR_ERR — Status of Interrupt from correctable error of corresponding CPUSet only if Interupt is unmasked in corresponding R5SS*_CPU*_ECC_CORR_ERRAGG_MASK registerWrie 0x1 to clear this interrupt.
  [4] R5SS0_CPU1_DDATA_CORR_ERR — Status of Interrupt from correctable error of corresponding CPUSet only if Interupt is unmasked in corresponding R5SS*_CPU*_ECC_CORR_ERRAGG_MASK registerWrie 0x1 to clear this interrupt.
  [3] R5SS0_CPU1_DTAG_CORR_ERR — Status of Interrupt from correctable error of corresponding CPUSet only if Interupt is unmasked in corresponding R5SS*_CPU*_ECC_CORR_ERRAGG_MASK registerWrie 0x1 to clear this interrupt.
  [2] R5SS0_CPU1_B0TCM_CORR_ERR — Status of Interrupt from correctable error of corresponding CPUSet only if Interupt is unmasked in corresponding R5SS*_CPU*_ECC_CORR_ERRAGG_MASK registerWrie 0x1 to clear this interrupt.
  [1] R5SS0_CPU1_B1TCM_CORR_ERR — Status of Interrupt from correctable error of corresponding CPUSet only if Interupt is unmasked in corresponding R5SS*_CPU*_ECC_CORR_ERRAGG_MASK registerWrie 0x1 to clear this interrupt.
  [0] R5SS0_CPU1_ATCM_CORR_ERR — Status of Interrupt from correctable error of corresponding CPUSet only if Interupt is unmasked in corresponding R5SS*_CPU*_ECC_CORR_ERRAGG_MASK registerWrie 0x1 to clear this interrupt.
0x180A8 MSS_CTRL_R5SS0_CPU1_ECC_CORR_ERRAGG_STATUS_RAW 8-bit rw
  [6] R5SS0_CPU1_IDATA_CORR_ERR — Raw Status of Interrupt from correctable error of corresponding CPUSet only if Interupt is unmasked in corresponding R5SS*_CPU*_ECC_CORR_ERRAGG_MASK registerWrie 0x1 to clear this interrupt.
  [5] R5SS0_CPU1_ITAG_CORR_ERR — Raw Status of Interrupt from correctable error of corresponding CPUSet only if Interupt is unmasked in corresponding R5SS*_CPU*_ECC_CORR_ERRAGG_MASK registerWrie 0x1 to clear this interrupt.
  [4] R5SS0_CPU1_DDATA_CORR_ERR — Raw Status of Interrupt from correctable error of corresponding CPUSet only if Interupt is unmasked in corresponding R5SS*_CPU*_ECC_CORR_ERRAGG_MASK registerWrie 0x1 to clear this interrupt.
  [3] R5SS0_CPU1_DTAG_CORR_ERR — Raw Status of Interrupt from correctable error of corresponding CPUSet only if Interupt is unmasked in corresponding R5SS*_CPU*_ECC_CORR_ERRAGG_MASK registerWrie 0x1 to clear this interrupt.
  [2] R5SS0_CPU1_B0TCM_CORR_ERR — Raw Status of Interrupt from correctable error of corresponding CPUSet only if Interupt is unmasked in corresponding R5SS*_CPU*_ECC_CORR_ERRAGG_MASK registerWrie 0x1 to clear this interrupt.
  [1] R5SS0_CPU1_B1TCM_CORR_ERR — Raw Status of Interrupt from correctable error of corresponding CPUSet only if Interupt is unmasked in corresponding R5SS*_CPU*_ECC_CORR_ERRAGG_MASK registerWrie 0x1 to clear this interrupt.
  [0] R5SS0_CPU1_ATCM_CORR_ERR — Raw Status of Interrupt from correctable error of corresponding CPUSet only if Interupt is unmasked in corresponding R5SS*_CPU*_ECC_CORR_ERRAGG_MASK registerWrie 0x1 to clear this interrupt.
0x180B0 MSS_CTRL_R5SS0_CPU1_ECC_UNCORR_ERRAGG_MASK 8-bit rw
  [4] R5SS0_CPU1_DDATA_UNCORR_ERR — Mask Interrupt for correctable errors to aggregated Interrupt of corresponding CPU1 : Interrupt is Masked0 : Interrupt is Unmasked
  [3] R5SS0_CPU1_DTAG_UNCORR_ERR — Mask Interrupt for correctable errors to aggregated Interrupt of corresponding CPU1 : Interrupt is Masked0 : Interrupt is Unmasked
  [2] R5SS0_CPU1_B0TCM_UNCORR_ERR — Mask Interrupt for correctable errors to aggregated Interrupt of corresponding CPU1 : Interrupt is Masked0 : Interrupt is Unmasked
  [1] R5SS0_CPU1_B1TCM_UNCORR_ERR — Mask Interrupt for correctable errors to aggregated Interrupt of corresponding CPU1 : Interrupt is Masked0 : Interrupt is Unmasked
  [0] R5SS0_CPU1_ATCM_UNCORR_ERR — Mask Interrupt for correctable errors to aggregated Interrupt of corresponding CPU1 : Interrupt is Masked0 : Interrupt is Unmasked
0x180B4 MSS_CTRL_R5SS0_CPU1_ECC_UNCORR_ERRAGG_STATUS 8-bit rw
  [4] R5SS0_CPU1_DDATA_UNCORR_ERR — Status of Interrupt from correctable error of corresponding CPUSet only if Interupt is unmasked in corresponding R5SS*_CPU*_ECC_UNCORR_ERRAGG_MASK registerWrie 0x1 to clear this interrupt.
  [3] R5SS0_CPU1_DTAG_UNCORR_ERR — Status of Interrupt from correctable error of corresponding CPUSet only if Interupt is unmasked in corresponding R5SS*_CPU*_ECC_UNCORR_ERRAGG_MASK registerWrie 0x1 to clear this interrupt.
  [2] R5SS0_CPU1_B0TCM_UNCORR_ERR — Status of Interrupt from correctable error of corresponding CPUSet only if Interupt is unmasked in corresponding R5SS*_CPU*_ECC_UNCORR_ERRAGG_MASK registerWrie 0x1 to clear this interrupt.
  [1] R5SS0_CPU1_B1TCM_UNCORR_ERR — Status of Interrupt from correctable error of corresponding CPUSet only if Interupt is unmasked in corresponding R5SS*_CPU*_ECC_UNCORR_ERRAGG_MASK registerWrie 0x1 to clear this interrupt.
  [0] R5SS0_CPU1_ATCM_UNCORR_ERR — Status of Interrupt from correctable error of corresponding CPUSet only if Interupt is unmasked in corresponding R5SS*_CPU*_ECC_UNCORR_ERRAGG_MASK registerWrie 0x1 to clear this interrupt.
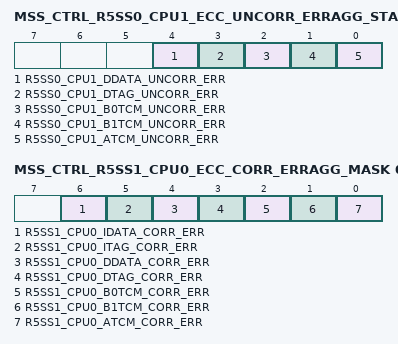
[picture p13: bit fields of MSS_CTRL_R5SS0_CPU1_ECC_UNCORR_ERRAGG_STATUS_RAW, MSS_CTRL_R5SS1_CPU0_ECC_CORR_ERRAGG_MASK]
0x180B8 MSS_CTRL_R5SS0_CPU1_ECC_UNCORR_ERRAGG_STATUS_RAW 8-bit rw
  [4] R5SS0_CPU1_DDATA_UNCORR_ERR — Raw Status of Interrupt from correctable error of corresponding CPUSet only if Interupt is unmasked in corresponding R5SS*_CPU*_ECC_UNCORR_ERRAGG_MASK registerWrie 0x1 to clear this interrupt.
  [3] R5SS0_CPU1_DTAG_UNCORR_ERR — Raw Status of Interrupt from correctable error of corresponding CPUSet only if Interupt is unmasked in corresponding R5SS*_CPU*_ECC_UNCORR_ERRAGG_MASK registerWrie 0x1 to clear this interrupt.
  [2] R5SS0_CPU1_B0TCM_UNCORR_ERR — Raw Status of Interrupt from correctable error of corresponding CPUSet only if Interupt is unmasked in corresponding R5SS*_CPU*_ECC_UNCORR_ERRAGG_MASK registerWrie 0x1 to clear this interrupt.
  [1] R5SS0_CPU1_B1TCM_UNCORR_ERR — Raw Status of Interrupt from correctable error of corresponding CPUSet only if Interupt is unmasked in corresponding R5SS*_CPU*_ECC_UNCORR_ERRAGG_MASK registerWrie 0x1 to clear this interrupt.
  [0] R5SS0_CPU1_ATCM_UNCORR_ERR — Raw Status of Interrupt from correctable error of corresponding CPUSet only if Interupt is unmasked in corresponding R5SS*_CPU*_ECC_UNCORR_ERRAGG_MASK registerWrie 0x1 to clear this interrupt.
0x180C0 MSS_CTRL_R5SS1_CPU0_ECC_CORR_ERRAGG_MASK 8-bit rw
  [6] R5SS1_CPU0_IDATA_CORR_ERR — Mask Interrupt for correctable errors to aggregated Interrupt of corresponding CPU1 : Interrupt is Masked0 : Interrupt is Unmasked
  [5] R5SS1_CPU0_ITAG_CORR_ERR — Mask Interrupt for correctable errors to aggregated Interrupt of corresponding CPU1 : Interrupt is Masked0 : Interrupt is Unmasked
  [4] R5SS1_CPU0_DDATA_CORR_ERR — Mask Interrupt for correctable errors to aggregated Interrupt of corresponding CPU1 : Interrupt is Masked0 : Interrupt is Unmasked
  [3] R5SS1_CPU0_DTAG_CORR_ERR — Mask Interrupt for correctable errors to aggregated Interrupt of corresponding CPU1 : Interrupt is Masked0 : Interrupt is Unmasked
  [2] R5SS1_CPU0_B0TCM_CORR_ERR — Mask Interrupt for correctable errors to aggregated Interrupt of corresponding CPU1 : Interrupt is Masked0 : Interrupt is Unmasked
  [1] R5SS1_CPU0_B1TCM_CORR_ERR — Mask Interrupt for correctable errors to aggregated Interrupt of corresponding CPU1 : Interrupt is Masked0 : Interrupt is Unmasked
  [0] R5SS1_CPU0_ATCM_CORR_ERR — Mask Interrupt for correctable errors to aggregated Interrupt of corresponding CPU1 : Interrupt is Masked0 : Interrupt is Unmasked
